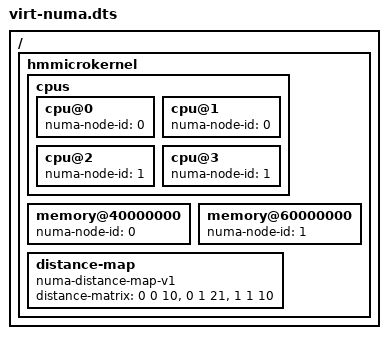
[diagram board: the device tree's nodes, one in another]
/dts-v1/;
/include/ "virt.dts"
/ {
	hmmicrokernel {
		cpus {
			cpu@0 {
				/* numa node 0 */
				numa-node-id = <0>;
			};
			cpu@1 {
				/* numa node 0 */
				numa-node-id = <0>;
			};
			cpu@2 {
				/* numa node 1 */
				numa-node-id = <1>;
			};
			cpu@3 {
				/* numa node 1 */
				numa-node-id = <1>;
			};
		};

		memory@40000000 {
			/* numa node 0 */
			numa-node-id = <0>;
		};

		memory@60000000 {
			/* numa node 1 */
			numa-node-id = <1>;
		};

		distance-map {
			compatible = "numa-distance-map-v1";
			distance-matrix = <0 0 10>,
					  <0 1 21>,
					  <1 1 10>;
		};
	};
};
